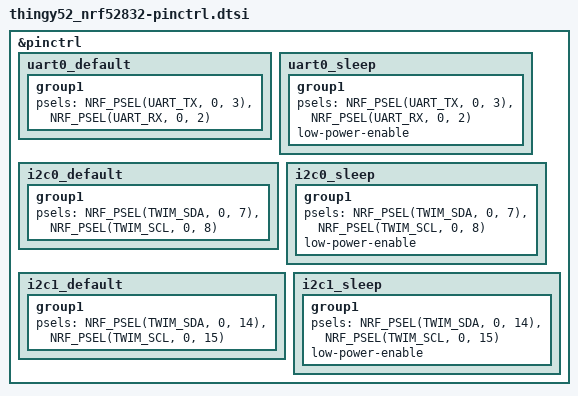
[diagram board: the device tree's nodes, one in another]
/*
 * Copyright (c) 2022 Nordic Semiconductor
 * SPDX-License-Identifier: Apache-2.0
 */

&pinctrl {
	uart0_default: uart0_default {
		group1 {
			psels = <NRF_PSEL(UART_TX, 0, 3)>,
				<NRF_PSEL(UART_RX, 0, 2)>;
		};
	};

	uart0_sleep: uart0_sleep {
		group1 {
			psels = <NRF_PSEL(UART_TX, 0, 3)>,
				<NRF_PSEL(UART_RX, 0, 2)>;
			low-power-enable;
		};
	};

	i2c0_default: i2c0_default {
		group1 {
			psels = <NRF_PSEL(TWIM_SDA, 0, 7)>,
				<NRF_PSEL(TWIM_SCL, 0, 8)>;
		};
	};

	i2c0_sleep: i2c0_sleep {
		group1 {
			psels = <NRF_PSEL(TWIM_SDA, 0, 7)>,
				<NRF_PSEL(TWIM_SCL, 0, 8)>;
			low-power-enable;
		};
	};

	i2c1_default: i2c1_default {
		group1 {
			psels = <NRF_PSEL(TWIM_SDA, 0, 14)>,
				<NRF_PSEL(TWIM_SCL, 0, 15)>;
		};
	};

	i2c1_sleep: i2c1_sleep {
		group1 {
			psels = <NRF_PSEL(TWIM_SDA, 0, 14)>,
				<NRF_PSEL(TWIM_SCL, 0, 15)>;
			low-power-enable;
		};
	};

};
